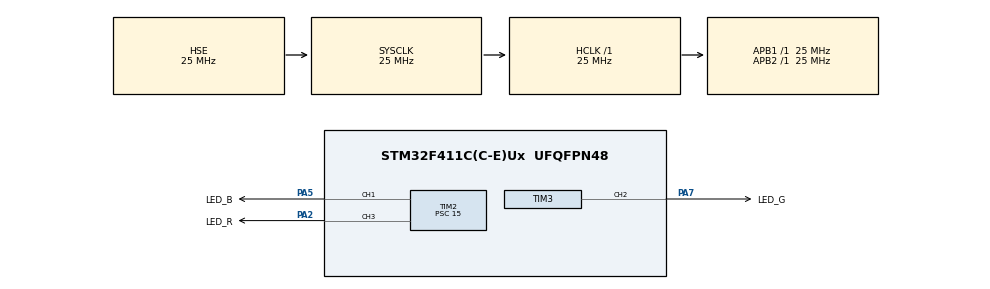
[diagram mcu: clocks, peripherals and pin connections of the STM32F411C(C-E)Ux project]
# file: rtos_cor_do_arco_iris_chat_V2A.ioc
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FREERTOS.Tasks01=rainbowTask,24,256,RainbowTask,Default,NULL,Dynamic,NULL,NULL
Mcu.Family=STM32F4
Mcu.Name=STM32F411C(C-E)Ux
Mcu.Package=UFQFPN48
NVIC.PriorityGroup=NVIC_PRIORITYGROUP_4
NVIC.TIM4_IRQn=true\:15\:0\:false\:false\:true\:false\:false\:true\:true
NVIC.TimeBase=TIM4_IRQn
NVIC.TimeBaseIP=TIM4
PA13.Mode=Serial_Wire
PA13.Signal=SYS_JTMS-SWDIO
PA14.Mode=Serial_Wire
PA14.Signal=SYS_JTCK-SWCLK
PA2.GPIO_Label=LED_R
PA2.Signal=S_TIM2_CH3
PA5.GPIO_Label=LED_B
PA5.Signal=S_TIM2_CH1_ETR
PA7.GPIO_Label=LED_G
PA7.Signal=S_TIM3_CH2
PH0\ -\ OSC_IN.Mode=HSE-External-Oscillator
PH0\ -\ OSC_IN.Signal=RCC_OSC_IN
PH1\ -\ OSC_OUT.Mode=HSE-External-Oscillator
PH1\ -\ OSC_OUT.Signal=RCC_OSC_OUT
ProjectManager.HeapSize=0x200
ProjectManager.StackSize=0x400
ProjectManager.TargetToolchain=STM32CubeIDE
RCC.48MHZClocksFreq_Value=75000000
RCC.AHBFreq_Value=25000000
RCC.APB1Freq_Value=25000000
RCC.APB1TimFreq_Value=25000000
RCC.APB2Freq_Value=25000000
RCC.APB2TimFreq_Value=25000000
RCC.CortexFreq_Value=25000000
RCC.HCLKFreq_Value=25000000
RCC.HSE_VALUE=25000000
RCC.HSI_VALUE=16000000
RCC.LSE_VALUE=32768
RCC.PLLSourceVirtual=RCC_PLLSOURCE_HSE
RCC.SYSCLKFreq_VALUE=25000000
RCC.SYSCLKSource=RCC_SYSCLKSOURCE_HSE
RCC.VCOOutputFreq_Value=300000000
SH.S_TIM2_CH1_ETR.0=TIM2_CH1,PWM Generation1 CH1
SH.S_TIM2_CH3.0=TIM2_CH3,PWM Generation3 CH3
SH.S_TIM3_CH2.0=TIM3_CH2,PWM Generation2 CH2
TIM2.Channel-PWM\ Generation1\ CH1=TIM_CHANNEL_1
TIM2.Channel-PWM\ Generation3\ CH3=TIM_CHANNEL_3
TIM2.Period=1023
TIM2.Prescaler=15
TIM3.Channel-PWM\ Generation2\ CH2=TIM_CHANNEL_2
TIM3.Period=1023
TIM3.Prescaler=15
VP_FREERTOS_VS_CMSIS_V2.Mode=CMSIS_V2
VP_SYS_VS_tim4.Mode=TIM4
board=custom

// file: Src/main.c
/* USER CODE BEGIN Header */
/**
  ******************************************************************************
  * @file           : main.c
  * @brief          : Main program body
  ******************************************************************************
  * @attention
  *
  * Copyright (c) 2026 STMicroelectronics.
  * All rights reserved.
  *
  * This software is licensed under terms that can be found in the LICENSE file
  * in the root directory of this software component.
  * If no LICENSE file comes with this software, it is provided AS-IS.
  *
  ******************************************************************************
  */
/* USER CODE END Header */
#include "main.h"
#include "cmsis_os.h"
#include "tim.h"
#include "gpio.h"

void SystemClock_Config(void);
void MX_FREERTOS_Init(void);

int main(void)
{

  /* MCU Configuration--------------------------------------------------------*/

  /* Reset of all peripherals, Initializes the Flash interface and the Systick. */
  HAL_Init();

  /* Configure the system clock */
  SystemClock_Config();

  /* Initialize all configured peripherals */
  MX_GPIO_Init();
  MX_TIM2_Init();
  MX_TIM3_Init();
  /* USER CODE BEGIN 2 */
  HAL_TIM_PWM_Start(&htim2, TIM_CHANNEL_1);
  HAL_TIM_PWM_Start(&htim2, TIM_CHANNEL_3);
  HAL_TIM_PWM_Start(&htim3, TIM_CHANNEL_2);
  /* USER CODE END 2 */

  /* Init scheduler */
  osKernelInitialize();  /* Call init function for freertos objects (in cmsis_os2.c) */
  MX_FREERTOS_Init();

  /* Start scheduler */
  osKernelStart();

  /* We should never get here as control is now taken by the scheduler */

  /* Infinite loop */
  while (1)
  {

  }
}

void SystemClock_Config(void)
{
  RCC_OscInitTypeDef RCC_OscInitStruct = {0};
  RCC_ClkInitTypeDef RCC_ClkInitStruct = {0};

  /** Configure the main internal regulator output voltage
  */
  __HAL_RCC_PWR_CLK_ENABLE();
  __HAL_PWR_VOLTAGESCALING_CONFIG(PWR_REGULATOR_VOLTAGE_SCALE1);

  /** Initializes the RCC Oscillators according to the specified parameters
  * in the RCC_OscInitTypeDef structure.
  */
  RCC_OscInitStruct.OscillatorType = RCC_OSCILLATORTYPE_HSE;
  RCC_OscInitStruct.HSEState = RCC_HSE_ON;
  RCC_OscInitStruct.PLL.PLLState = RCC_PLL_NONE;
  if (HAL_RCC_OscConfig(&RCC_OscInitStruct) != HAL_OK)
  {
    Error_Handler();
  }

  /** Initializes the CPU, AHB and APB buses clocks
  */
  RCC_ClkInitStruct.ClockType = RCC_CLOCKTYPE_HCLK|RCC_CLOCKTYPE_SYSCLK
                              |RCC_CLOCKTYPE_PCLK1|RCC_CLOCKTYPE_PCLK2;
  RCC_ClkInitStruct.SYSCLKSource = RCC_SYSCLKSOURCE_HSE;
  RCC_ClkInitStruct.AHBCLKDivider = RCC_SYSCLK_DIV1;
  RCC_ClkInitStruct.APB1CLKDivider = RCC_HCLK_DIV1;
  RCC_ClkInitStruct.APB2CLKDivider = RCC_HCLK_DIV1;

  if (HAL_RCC_ClockConfig(&RCC_ClkInitStruct, FLASH_LATENCY_0) != HAL_OK)
  {
    Error_Handler();
  }
}

void HAL_TIM_PeriodElapsedCallback(TIM_HandleTypeDef *htim)
{
  if (htim->Instance == TIM4)
  {
    HAL_IncTick();
  }
}

void Error_Handler(void)
{
  __disable_irq();
  while (1)
  {
  }
}

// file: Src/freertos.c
/* USER CODE BEGIN Header */
/**
   ******************************************************************************
  * @file           : freertos.c
  * @brief          : Controle de LED RGB com transições suaves via PWM (FreeRTOS)
  * @author         : Pedro Henrique Guerra
  * @date           : 20/04/2026
  *
  * @details
  * Este módulo implementa a geração de cores dinâmicas em um LED RGB
  * utilizando modulação por largura de pulso (PWM) controlada por timers.
  *
  * O sistema percorre uma sequência de cores predefinidas (arco-íris),
  * aplicando transições suaves entre elas por meio de interpolação linear.
  *
  * A execução é realizada dentro de uma task do FreeRTOS, garantindo
  * comportamento não bloqueante para o restante do sistema (com exceção
  * da função de transição, que utiliza delay interno controlado).
  *
  * ---------------------------------------------------------------------------
  * Arquitetura:
  *
  * Task (RainbowTask)
  *     ↓
  * Seleção de cor da tabela
  *     ↓
  * Aplicação direta (set_rgb)
  *     ↓
  * Transição suave (interpolação)
  *     ↓
  * Atualização PWM (TIM CCR)
  *
  * ---------------------------------------------------------------------------
  * Características:
  *
  * - Controle direto de hardware via registradores CCR
  * - Transições suaves com interpolação linear
  * - Sequência cíclica de cores (efeito arco-íris)
  * - Baixo custo computacional
  *
  ******************************************************************************
  * @attention
  *
  * Copyright (c) 2026 STMicroelectronics.
  * All rights reserved.
  *
  * This software is licensed under terms that can be found in the LICENSE file
  * in the root directory of this software component.
  * If no LICENSE file comes with this software, it is provided AS-IS.
  *
  ******************************************************************************
  */
/* USER CODE END Header */

#include "FreeRTOS.h"
#include "task.h"
#include "main.h"
#include "cmsis_os.h"

/* USER CODE BEGIN Includes */
#include "tim.h"
/* USER CODE END Includes */

/* USER CODE BEGIN PD */
/**
 * @def PWM_STEPS
 * @brief Número de passos utilizados para interpolação entre duas cores.
 */
#define PWM_STEPS      100
/**
 * @def COLOR_HOLD_MS
 * @brief Tempo em milissegundos que cada cor permanece estática.
 */
#define COLOR_HOLD_MS  3000
/**
 * @def TRANSITION_MS
 * @brief Tempo total da transição entre duas cores consecutivas.
 */
#define TRANSITION_MS  2000
/**
 * @def RAINBOW_SIZE
 * @brief Número total de cores presentes na tabela de cores do arco-íris.
 */
#define RAINBOW_SIZE (sizeof(rainbow) / sizeof(rainbow[0]))
/* USER CODE END PD */

/* USER CODE BEGIN PM */

/**
 * @brief Tabela de cores do espectro arco-íris.
 *
 * Cada entrada representa uma cor no formato:
 * {R, G, B}
 *
 * Os valores correspondem ao duty cycle aplicado ao PWM
 * de cada canal RGB.
 */
static const uint16_t rainbow[][3] =
{
    {1023,   0,   0},   /**< Vermelho */
    {1023, 165,   0},   /**< Laranja */
    {1023,1023,   0},   /**< Amarelo */
    {   0,1023,   0},   /**< Verde */
    {   0,   0,1023},   /**< Azul */
    {  75,   0, 130},   /**< Anil */
    { 238, 130, 238}    /**< Violeta */
};
/* USER CODE END PM */

/* Definitions for rainbowTask */
osThreadId_t rainbowTaskHandle;
const osThreadAttr_t rainbowTask_attributes = {
  .name = "rainbowTask",
  .stack_size = 256 * 4,
  .priority = (osPriority_t) osPriorityNormal,
};

/* USER CODE BEGIN FunctionPrototypes */
static void transition(const uint16_t *from, const uint16_t *to);
static void set_rgb(uint16_t r, uint16_t g, uint16_t b);
/* USER CODE END FunctionPrototypes */

void RainbowTask(void *argument);

void MX_FREERTOS_Init(void); /* (MISRA C 2004 rule 8.1) */

void MX_FREERTOS_Init(void) {

  /* Create the thread(s) */
  /* creation of rainbowTask */
  rainbowTaskHandle = osThreadNew(RainbowTask, NULL, &rainbowTask_attributes);

}

/* USER CODE BEGIN Header_RainbowTask */
/**
  * @brief Task responsável pelo controle dinâmico das cores do LED RGB.
  *
  * @details
  * Esta task executa continuamente um ciclo de cores baseado
  * na tabela @ref rainbow.
  *
  * Para cada cor:
  * 1. Aplica a cor diretamente ao LED
  * 2. Aguarda um período fixo (@ref COLOR_HOLD_MS)
  * 3. Realiza transição suave para a próxima cor
  *
  * Ao final da sequência:
  * - Desliga o LED
  * - Aguarda antes de reiniciar o ciclo
  *
  * @note A transição utiliza delay interno, portanto a task
  *       ocupa CPU durante esse período.
  *
  * @param argument Parâmetro não utilizado
  */
/* USER CODE END Header_RainbowTask */
void RainbowTask(void *argument)
{
  /* USER CODE BEGIN RainbowTask */
  /* Infinite loop */
	while(1)
	    {
	        for (uint32_t i = 0; i < RAINBOW_SIZE; i++)
	        {
	            set_rgb(rainbow[i][0], rainbow[i][1], rainbow[i][2]);

	            osDelay(COLOR_HOLD_MS);

	            if (i < RAINBOW_SIZE - 1)
	            {
	                transition(rainbow[i], rainbow[i+1]);
	            }
	        }

	        set_rgb(0,0,0);

	        osDelay(2000); // pausa antes de reiniciar
	    }
  /* USER CODE END RainbowTask */
}

/* USER CODE BEGIN Application */
/**
 * @brief Atualiza os duty cycles PWM dos canais RGB.
 *
 * @param r Valor PWM do canal vermelho
 * @param g Valor PWM do canal verde
 * @param b Valor PWM do canal azul
 *
 * @details
 * Cada valor é aplicado diretamente ao registrador CCR
 * correspondente do timer responsável pelo canal PWM.
 */

static void set_rgb(uint16_t r, uint16_t g, uint16_t b)
{
    __HAL_TIM_SET_COMPARE(&htim2, TIM_CHANNEL_1, r);
    __HAL_TIM_SET_COMPARE(&htim3, TIM_CHANNEL_2, g);
    __HAL_TIM_SET_COMPARE(&htim2, TIM_CHANNEL_3, b);
}

/**
 * @brief Realiza transição suave entre duas cores.
 *
 * @param from Ponteiro para a cor inicial no formato RGB.
 * @param to Ponteiro para a cor final no formato RGB.
 *
 * @details
 * A transição é feita através de interpolação linear em
 * @ref PWM_STEPS passos, atualizando gradualmente os valores
 * PWM de cada canal.
 */

static void transition(const uint16_t *from, const uint16_t *to)
{
    for (uint32_t i = 0; i < PWM_STEPS; i++)
    {
        uint16_t r = from[0] + (i * (to[0] - from[0])) / PWM_STEPS;
        uint16_t g = from[1] + (i * (to[1] - from[1])) / PWM_STEPS;
        uint16_t b = from[2] + (i * (to[2] - from[2])) / PWM_STEPS;

        set_rgb(r,g,b);

        HAL_Delay(TRANSITION_MS / PWM_STEPS);
    }
}
/* USER CODE END Application */
